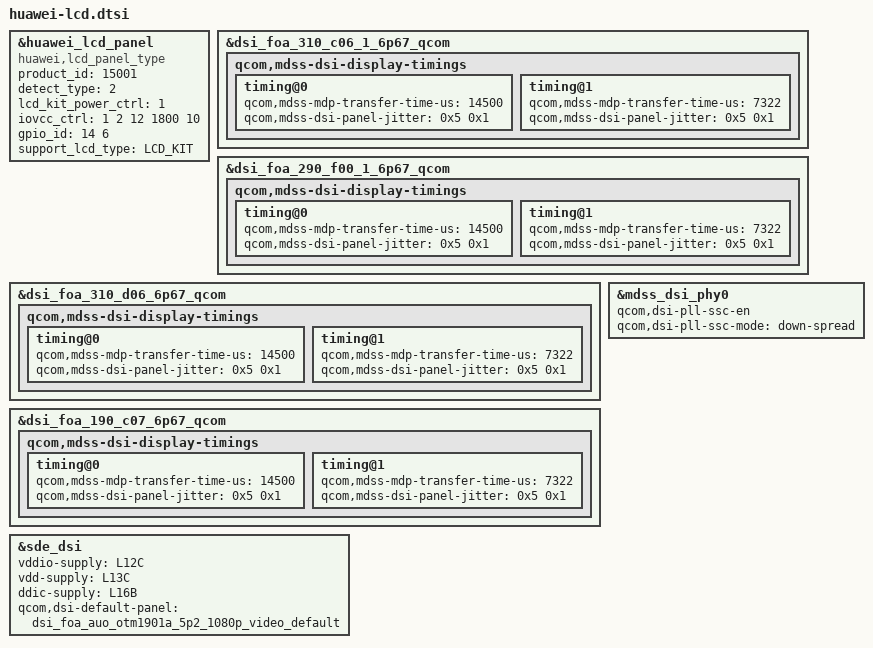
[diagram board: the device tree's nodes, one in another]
#include "../../../lcdkit3.0/foa/devkit_lcd_kit.dtsi"
&huawei_lcd_panel {
	compatible = "huawei,lcd_panel_type";
	/* auto_key_info @ name: product_id type: uint32 default: 0 */
	product_id = <15001>;
	detect_type = <2>;
	/* auto_key_info @ name: lcd_kit_power_ctrl type: uint32 default: 0 */
	lcd_kit_power_ctrl = <1>;
	/* iovcc_ctrl: byte-1:power mode(1:ldo, 2:gpio), byte-2: pmic id,  byte-3: ldo id, byte-4: ldo value, byte-5: delay */
	/* auto_key_info @ name: iovcc_ctrl[5] type: uint32 default: 0 */
	iovcc_ctrl = <1 2 12 1800 10>;
	/* auto_key_info @ name: gpio_id[2] type: int default: 0 */
	gpio_id = <14 6>;
	support_lcd_type = "LCD_KIT";
};
&dsi_foa_310_c06_1_6p67_qcom {
	qcom,mdss-dsi-display-timings {
		timing@0 {
			qcom,mdss-mdp-transfer-time-us = <14500>;
			qcom,mdss-dsi-panel-jitter = <0x5 0x1>;
		};
		timing@1 {
			qcom,mdss-mdp-transfer-time-us = <7322>;
			qcom,mdss-dsi-panel-jitter = <0x5 0x1>;
		};
	};
};
&dsi_foa_290_f00_1_6p67_qcom {
	qcom,mdss-dsi-display-timings {
		timing@0 {
			qcom,mdss-mdp-transfer-time-us = <14500>;
			qcom,mdss-dsi-panel-jitter = <0x5 0x1>;
		};
		timing@1 {
			qcom,mdss-mdp-transfer-time-us = <7322>;
			qcom,mdss-dsi-panel-jitter = <0x5 0x1>;
		};
	};
};
&dsi_foa_310_d06_6p67_qcom {
	qcom,mdss-dsi-display-timings {
		timing@0 {
			qcom,mdss-mdp-transfer-time-us = <14500>;
			qcom,mdss-dsi-panel-jitter = <0x5 0x1>;
		};
		timing@1 {
			qcom,mdss-mdp-transfer-time-us = <7322>;
			qcom,mdss-dsi-panel-jitter = <0x5 0x1>;
		};
	};
};
&dsi_foa_190_c07_6p67_qcom {
	qcom,mdss-dsi-display-timings {
		timing@0 {
			qcom,mdss-mdp-transfer-time-us = <14500>;
			qcom,mdss-dsi-panel-jitter = <0x5 0x1>;
		};
		timing@1 {
			qcom,mdss-mdp-transfer-time-us = <7322>;
			qcom,mdss-dsi-panel-jitter = <0x5 0x1>;
		};
	};
};
&sde_dsi {
	vddio-supply = <&L12C>;
	vdd-supply = <&L13C>;
	ddic-supply = <&L16B>;
	qcom,dsi-default-panel = <&dsi_foa_auo_otm1901a_5p2_1080p_video_default>;
};
&mdss_dsi_phy0 {
    qcom,dsi-pll-ssc-en;
    qcom,dsi-pll-ssc-mode = "down-spread";
};
